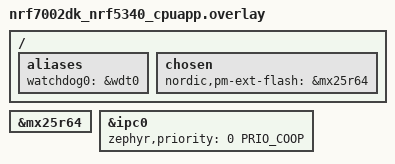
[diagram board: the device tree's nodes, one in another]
/*
 * Copyright (c) 2021 Nordic Semiconductor ASA
 *
 * SPDX-License-Identifier: LicenseRef-Nordic-5-Clause
 */

#include <samples/matter/nrf7002_cpuapp_partitions.dtsi>
#include <zephyr/dt-bindings/ipc_service/static_vrings.h>

/ {
	aliases {
		watchdog0 = &wdt0;
	};

	chosen {
		nordic,pm-ext-flash = &mx25r64;
	};
};

&mx25r64 {
	status = "okay";
};

/* Set IPC thread priority to the highest value to not collide with other threads. */
&ipc0 {
	zephyr,priority = <0 PRIO_COOP>;
};
